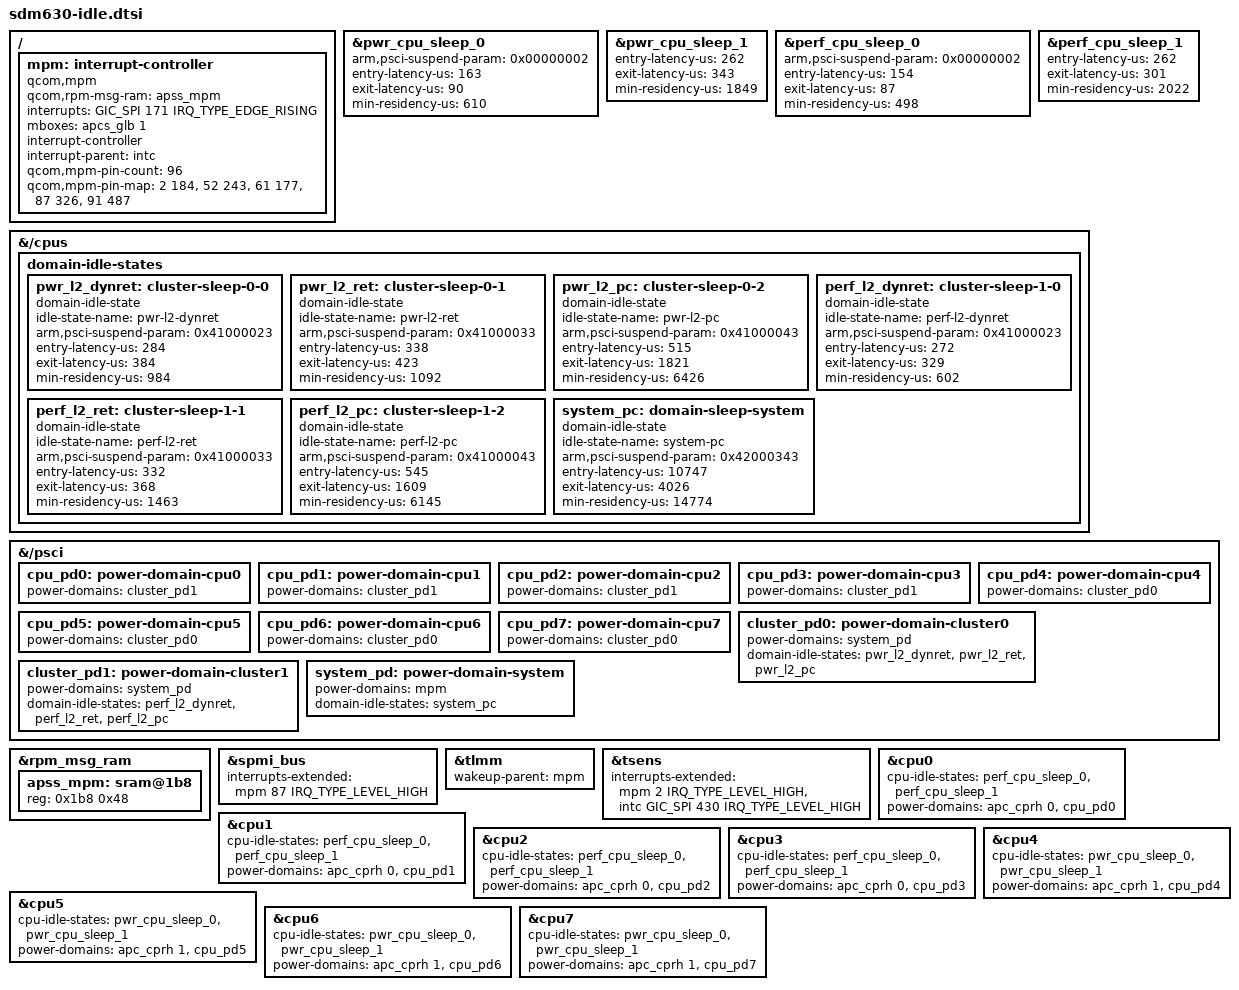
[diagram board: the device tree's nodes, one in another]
// SPDX-License-Identifier: BSD-3-Clause
/*
 * SDM630 CPU and cluster (L2) idle for PSCI OS-initiated mode.
 * Include after sdm630-dvfs.dtsi: the CPU power-domains lists extend its
 * "cpr" entries.
 *
 * The firmware composes the power_state the way the vendor lpm-levels
 * driver does (psci_enter_sleep(), get_cluster_id()):
 *
 *   is_reset(CPU level) << 30 | affinity level << 24 | L2 mode << 4 | CPU mode
 *
 * CPU modes: 1 WFI, 2 retention, 3 power collapse. L2 modes: 2 dynamic
 * retention, 3 retention, 4 power collapse. Only the last CPU of a cluster
 * adds an L2 mode, raising the affinity level to 1. CPU retention is not a
 * reset state, hence 0x00000002. sdm630.dtsi's flat cluster states
 * (0x400000f2..f4, requested by any CPU) are not in that encoding and the
 * firmware fails them at once, as it does 0x40000002.
 *
 * The L2 states hang off one PSCI domain per cluster, which genpd powers
 * off only once every CPU of the cluster is in CPU power collapse; each
 * carries the full request of that last CPU (CPU PC, affinity level 1,
 * L2 mode).
 *
 * Timings come from the stock qcom,lpm-levels nodes:
 *   exit-latency-us  = qcom,latency-us
 *   entry-latency-us = qcom,time-overhead - qcom,latency-us
 *   min-residency-us = one more than the shallower level's break-even
 *                      residency, computed from qcom,ss-power,
 *                      energy-overhead and time-overhead as the vendor
 *                      driver does (set_optimum_cpu_residency())
 *
 * The system level is the stock "system-pc" level: CCI power collapse,
 * psci-mode 3 at shift 8 on top of CPU and L2 power collapse, affinity
 * level 2: 0x42000343. Stock enters it only with both clusters in L2 power
 * collapse (qcom,min-child-idx = 3), which genpd also gives: its residency
 * is longer than either L2 power collapse. It has qcom,notify-rpm: the
 * vMPM gets the next timer event and the wakeup interrupt setup, and RPM
 * is kicked through the APCS IPC register. The MPM is the parent of the
 * system domain and does that in its genpd power_off.
 */

&pwr_cpu_sleep_0 {
	arm,psci-suspend-param = <0x00000002>;
	entry-latency-us = <163>;
	exit-latency-us = <90>;
	min-residency-us = <610>;
};

&pwr_cpu_sleep_1 {
	entry-latency-us = <262>;
	exit-latency-us = <343>;
	min-residency-us = <1849>;
};

&perf_cpu_sleep_0 {
	arm,psci-suspend-param = <0x00000002>;
	entry-latency-us = <154>;
	exit-latency-us = <87>;
	min-residency-us = <498>;
};

&perf_cpu_sleep_1 {
	entry-latency-us = <262>;
	exit-latency-us = <301>;
	min-residency-us = <2022>;
};

/delete-node/ &pwr_cluster_sleep_0;
/delete-node/ &pwr_cluster_sleep_1;
/delete-node/ &pwr_cluster_sleep_2;
/delete-node/ &perf_cluster_sleep_0;
/delete-node/ &perf_cluster_sleep_1;
/delete-node/ &perf_cluster_sleep_2;

&{/cpus} {
	domain-idle-states {
		pwr_l2_dynret: cluster-sleep-0-0 {
			compatible = "domain-idle-state";
			idle-state-name = "pwr-l2-dynret";
			arm,psci-suspend-param = <0x41000023>;
			entry-latency-us = <284>;
			exit-latency-us = <384>;
			min-residency-us = <984>;
		};

		pwr_l2_ret: cluster-sleep-0-1 {
			compatible = "domain-idle-state";
			idle-state-name = "pwr-l2-ret";
			arm,psci-suspend-param = <0x41000033>;
			entry-latency-us = <338>;
			exit-latency-us = <423>;
			min-residency-us = <1092>;
		};

		pwr_l2_pc: cluster-sleep-0-2 {
			compatible = "domain-idle-state";
			idle-state-name = "pwr-l2-pc";
			arm,psci-suspend-param = <0x41000043>;
			entry-latency-us = <515>;
			exit-latency-us = <1821>;
			min-residency-us = <6426>;
		};

		perf_l2_dynret: cluster-sleep-1-0 {
			compatible = "domain-idle-state";
			idle-state-name = "perf-l2-dynret";
			arm,psci-suspend-param = <0x41000023>;
			entry-latency-us = <272>;
			exit-latency-us = <329>;
			min-residency-us = <602>;
		};

		perf_l2_ret: cluster-sleep-1-1 {
			compatible = "domain-idle-state";
			idle-state-name = "perf-l2-ret";
			arm,psci-suspend-param = <0x41000033>;
			entry-latency-us = <332>;
			exit-latency-us = <368>;
			min-residency-us = <1463>;
		};

		perf_l2_pc: cluster-sleep-1-2 {
			compatible = "domain-idle-state";
			idle-state-name = "perf-l2-pc";
			arm,psci-suspend-param = <0x41000043>;
			entry-latency-us = <545>;
			exit-latency-us = <1609>;
			min-residency-us = <6145>;
		};

		system_pc: domain-sleep-system {
			compatible = "domain-idle-state";
			idle-state-name = "system-pc";
			arm,psci-suspend-param = <0x42000343>;
			entry-latency-us = <10747>;
			exit-latency-us = <4026>;
			min-residency-us = <14774>;
		};
	};
};

&{/psci} {
	/* cpu@100-103: performance cluster */
	cpu_pd0: power-domain-cpu0 {
		#power-domain-cells = <0>;
		power-domains = <&cluster_pd1>;
	};

	cpu_pd1: power-domain-cpu1 {
		#power-domain-cells = <0>;
		power-domains = <&cluster_pd1>;
	};

	cpu_pd2: power-domain-cpu2 {
		#power-domain-cells = <0>;
		power-domains = <&cluster_pd1>;
	};

	cpu_pd3: power-domain-cpu3 {
		#power-domain-cells = <0>;
		power-domains = <&cluster_pd1>;
	};

	/* cpu@0-3: power cluster */
	cpu_pd4: power-domain-cpu4 {
		#power-domain-cells = <0>;
		power-domains = <&cluster_pd0>;
	};

	cpu_pd5: power-domain-cpu5 {
		#power-domain-cells = <0>;
		power-domains = <&cluster_pd0>;
	};

	cpu_pd6: power-domain-cpu6 {
		#power-domain-cells = <0>;
		power-domains = <&cluster_pd0>;
	};

	cpu_pd7: power-domain-cpu7 {
		#power-domain-cells = <0>;
		power-domains = <&cluster_pd0>;
	};

	cluster_pd0: power-domain-cluster0 {
		#power-domain-cells = <0>;
		power-domains = <&system_pd>;
		domain-idle-states = <&pwr_l2_dynret>, <&pwr_l2_ret>, <&pwr_l2_pc>;
	};

	cluster_pd1: power-domain-cluster1 {
		#power-domain-cells = <0>;
		power-domains = <&system_pd>;
		domain-idle-states = <&perf_l2_dynret>, <&perf_l2_ret>, <&perf_l2_pc>;
	};

	system_pd: power-domain-system {
		#power-domain-cells = <0>;
		power-domains = <&mpm>;
		domain-idle-states = <&system_pc>;
	};
};

/*
 * MPM wakeup interrupt controller, from the stock qcom,mpm@7781b8 node
 * (qcom,mpm-v2): vMPM at 0x7781b8 in the RPM message RAM, IPC through APCS
 * IPC bit 1, SPI 171 rising. qcom,gic-map pairs are <pin, SPI + 32>; the
 * pins below carry the interrupts the mainline DT routes through the MPM.
 * Stock also maps pins 49 (SPI 180, dwc3 pwr_event) and 79 (SPI 347, dwc3
 * hs_phy); USB plug wakeup comes from the PM660 charger over SPMI instead.
 * The GPIO map is pinctrl-sdm660.c's sdm660_mpm_map.
 */
/ {
	mpm: interrupt-controller {
		compatible = "qcom,mpm";
		qcom,rpm-msg-ram = <&apss_mpm>;
		interrupts = <GIC_SPI 171 IRQ_TYPE_EDGE_RISING>;
		mboxes = <&apcs_glb 1>;
		interrupt-controller;
		#interrupt-cells = <2>;
		#power-domain-cells = <0>;
		interrupt-parent = <&intc>;
		qcom,mpm-pin-count = <96>;
		qcom,mpm-pin-map = <2 184>,	/* tsens uplow */
				   <52 243>,	/* dwc3 ss_phy_irq */
				   <61 177>,	/* wcd9xxx-irq (lpass) */
				   <87 326>,	/* SPMI periph_irq */
				   <91 487>;
	};
};

&rpm_msg_ram {
	#address-cells = <1>;
	#size-cells = <1>;
	ranges = <0 0x00778000 0x7000>;

	apss_mpm: sram@1b8 {
		reg = <0x1b8 0x48>;
	};
};

/* PMIC interrupts (power key, volume keys, RTC alarm, charger) wake through the MPM */
&spmi_bus {
	/delete-property/ interrupts;
	interrupts-extended = <&mpm 87 IRQ_TYPE_LEVEL_HIGH>;
};

&tlmm {
	wakeup-parent = <&mpm>;
};

&tsens {
	/delete-property/ interrupts;
	interrupts-extended = <&mpm 2 IRQ_TYPE_LEVEL_HIGH>,
			      <&intc GIC_SPI 430 IRQ_TYPE_LEVEL_HIGH>;
};

&cpu0 {
	cpu-idle-states = <&perf_cpu_sleep_0>, <&perf_cpu_sleep_1>;
	power-domains = <&apc_cprh 0>, <&cpu_pd0>;
	power-domain-names = "cpr", "psci";
};

&cpu1 {
	cpu-idle-states = <&perf_cpu_sleep_0>, <&perf_cpu_sleep_1>;
	power-domains = <&apc_cprh 0>, <&cpu_pd1>;
	power-domain-names = "cpr", "psci";
};

&cpu2 {
	cpu-idle-states = <&perf_cpu_sleep_0>, <&perf_cpu_sleep_1>;
	power-domains = <&apc_cprh 0>, <&cpu_pd2>;
	power-domain-names = "cpr", "psci";
};

&cpu3 {
	cpu-idle-states = <&perf_cpu_sleep_0>, <&perf_cpu_sleep_1>;
	power-domains = <&apc_cprh 0>, <&cpu_pd3>;
	power-domain-names = "cpr", "psci";
};

&cpu4 {
	cpu-idle-states = <&pwr_cpu_sleep_0>, <&pwr_cpu_sleep_1>;
	power-domains = <&apc_cprh 1>, <&cpu_pd4>;
	power-domain-names = "cpr", "psci";
};

&cpu5 {
	cpu-idle-states = <&pwr_cpu_sleep_0>, <&pwr_cpu_sleep_1>;
	power-domains = <&apc_cprh 1>, <&cpu_pd5>;
	power-domain-names = "cpr", "psci";
};

&cpu6 {
	cpu-idle-states = <&pwr_cpu_sleep_0>, <&pwr_cpu_sleep_1>;
	power-domains = <&apc_cprh 1>, <&cpu_pd6>;
	power-domain-names = "cpr", "psci";
};

&cpu7 {
	cpu-idle-states = <&pwr_cpu_sleep_0>, <&pwr_cpu_sleep_1>;
	power-domains = <&apc_cprh 1>, <&cpu_pd7>;
	power-domain-names = "cpr", "psci";
};
